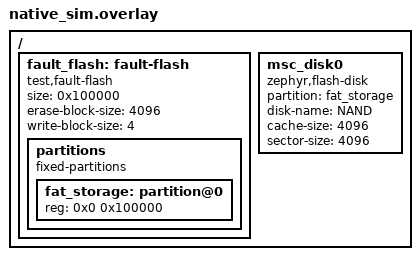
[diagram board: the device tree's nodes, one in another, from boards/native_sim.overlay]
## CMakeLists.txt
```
# SPDX-License-Identifier: Apache-2.0

cmake_minimum_required(VERSION 3.20.0)

# The overlay's test,fault-flash node uses this suite's local binding
# (dts/bindings) -- must be on DTS_ROOT before Zephyr is loaded.
list(APPEND DTS_ROOT ${CMAKE_CURRENT_LIST_DIR})

find_package(Zephyr REQUIRED HINTS $ENV{ZEPHYR_BASE})
project(fat_flashdisk_fault_tests)

# The patched flashdisk driver copy (fw/drivers/flashdisk). In the
# .sdk_tripwire scenario CONFIG_DISK_DRIVER_FLASH_PATCHED=n and this adds
# nothing -- the SDK driver builds instead.
add_subdirectory(
	${CMAKE_CURRENT_LIST_DIR}/../../../drivers
	${CMAKE_CURRENT_BINARY_DIR}/app_drivers
)

target_sources(app PRIVATE src/main.cpp src/fault_flash.c)
```

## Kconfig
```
source "Kconfig.zephyr"

rsource "../../../drivers/Kconfig"

# The fault_flash test driver has no Kconfig of its own (it is an app source);
# this promptless symbol supplies the flash-capability selects a driver
# Kconfig would normally make, so flashdisk_with_erase() and the page-layout
# verification see a real erase-required device.
config TEST_FAULT_FLASH
	bool
	default y
	select FLASH_HAS_EXPLICIT_ERASE
	select FLASH_HAS_PAGE_LAYOUT
	select FLASH_HAS_DRIVER_ENABLED
```

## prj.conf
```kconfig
CONFIG_ZTEST=y
CONFIG_CPP=y
CONFIG_STD_CPP2B=y
CONFIG_REQUIRES_FULL_LIBCPP=y
CONFIG_REQUIRES_FULL_LIBC=y
CONFIG_FLASH=y
CONFIG_FLASH_MAP=y
CONFIG_FLASH_PAGE_LAYOUT=y
CONFIG_FILE_SYSTEM=y
CONFIG_FAT_FILESYSTEM_ELM=y
CONFIG_FILE_SYSTEM_MKFS=y
CONFIG_DISK_ACCESS=y
CONFIG_HEAP_MEM_POOL_SIZE=16384

# Proto0 disk geometry: FatFS sector == flash erase page == 4096 (the SDK
# default of 512 would silently change the failure surface under test).
CONFIG_FS_FATFS_MAX_SS=4096

# Mirror proto0's FatFS threading configuration (issue #380 layer 2) so this
# suite builds and exercises the FS stack the device actually runs — review
# finding: before this, no native_sim build compiled FS_FATFS_REENTRANT at
# all. The concurrency hammer test depends on these.
CONFIG_FS_FATFS_LFN=y
CONFIG_FS_FATFS_LFN_MODE_STACK=y
CONFIG_FS_FATFS_REENTRANT=y

# The unit under test — the issue #380 backport. The .sdk_tripwire scenario
# overrides both to build against the SDK driver instead.
CONFIG_DISK_DRIVER_FLASH=n
CONFIG_DISK_DRIVER_FLASH_PATCHED=y
```

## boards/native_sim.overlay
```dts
/*
 * A fault-injectable flash controller under the same fat_storage/flash-disk
 * shape proto0 uses, but with proto0's REAL disk geometry (sector-size 4096 ==
 * erase page == FatFS sector, matching the Partition Manager extra_params),
 * unlike fat_corrupt's 512-byte sectors. The fault_flash driver in src/ backs
 * it with RAM and fails flash ops on command, which is the only way to
 * exercise the flashdisk error paths FatFS depends on (issue #380).
 */
/ {
	fault_flash: fault-flash {
		compatible = "test,fault-flash";
		size = <0x100000>;		/* 1 MB — f_mkfs needs >= 128 sectors at 4 KB */
		erase-block-size = <4096>;
		write-block-size = <4>;
		#address-cells = <1>;
		#size-cells = <1>;

		partitions {
			compatible = "fixed-partitions";
			#address-cells = <1>;
			#size-cells = <1>;

			fat_storage: partition@0 {
				reg = <0x0 0x100000>;
			};
		};
	};

	msc_disk0 {
		compatible = "zephyr,flash-disk";
		partition = <&fat_storage>;
		disk-name = "NAND";
		cache-size = <4096>;
		sector-size = <4096>;
	};
};
```

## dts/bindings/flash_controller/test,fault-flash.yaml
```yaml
# Test-only binding for the fat_flashdisk_fault suite. Lives inside the test
# directory (DTS_ROOT appended in its CMakeLists.txt) so the compatible never
# leaks into real board DTS.

description: RAM-backed flash controller with injectable per-op failures (issue #380 suite)

compatible: "test,fault-flash"

include: base.yaml

properties:
  size:
    type: int
    required: true
    description: Total backing-store size in bytes

  erase-block-size:
    type: int
    required: true
    description: Uniform erase page size in bytes

  write-block-size:
    type: int
    required: true
    description: Program alignment in bytes
```

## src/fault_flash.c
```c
/*
 * Test-only RAM-backed flash driver with injectable failures.
 *
 * Backs the fat_storage partition in this suite's native_sim overlay. Same
 * app-source-driver style the repo's emulator suites use — no Kconfig of its
 * own, capabilities are selected by the suite-local Kconfig (TEST_FAULT_FLASH).
 */

#define DT_DRV_COMPAT test_fault_flash

#include "fault_flash.h"

#include <string.h>
#include <zephyr/device.h>
#include <zephyr/drivers/flash.h>
#include <zephyr/kernel.h>

#define BACKING_SIZE DT_INST_PROP(0, size)
#define ERASE_BLOCK  DT_INST_PROP(0, erase_block_size)
#define WRITE_BLOCK  DT_INST_PROP(0, write_block_size)

BUILD_ASSERT(BACKING_SIZE % ERASE_BLOCK == 0, "size must be a whole number of erase blocks");

static uint8_t backing[BACKING_SIZE];

static struct {
	unsigned int op_mask;
	unsigned int remaining;
	off_t win_start;
	size_t win_len;
	unsigned int injected;
	unsigned int op_delay_ms;
} fault;

void fault_flash_set_op_delay_ms(unsigned int ms)
{
	fault.op_delay_ms = ms;
}

static void op_delay(void)
{
	if (fault.op_delay_ms != 0) {
		k_msleep(fault.op_delay_ms);
	}
}

void fault_flash_arm(unsigned int op_mask, unsigned int count, off_t win_start, size_t win_len)
{
	fault.op_mask = op_mask;
	fault.remaining = count;
	fault.win_start = win_start;
	fault.win_len = win_len;
	fault.injected = 0;
}

void fault_flash_disarm(void)
{
	fault_flash_arm(0, 0, 0, 0);
	fault.op_delay_ms = 0;
}

unsigned int fault_flash_injected(void)
{
	return fault.injected;
}

static bool fault_hits(unsigned int op, off_t addr, size_t len)
{
	if ((fault.op_mask & op) == 0 || fault.remaining == 0) {
		return false;
	}
	if (fault.win_len != 0 &&
	    ((addr + (off_t)len <= fault.win_start) ||
	     (addr >= fault.win_start + (off_t)fault.win_len))) {
		return false;
	}
	fault.remaining--;
	fault.injected++;
	return true;
}

static bool in_bounds(off_t offset, size_t len)
{
	return offset >= 0 && len <= (size_t)BACKING_SIZE && (size_t)offset <= BACKING_SIZE - len;
}

static int fault_flash_read(const struct device *dev, off_t offset, void *data, size_t len)
{
	ARG_UNUSED(dev);
	op_delay();
	if (!in_bounds(offset, len)) {
		return -EINVAL;
	}
	if (fault_hits(FAULT_FLASH_OP_READ, offset, len)) {
		return -EIO;
	}
	memcpy(data, &backing[offset], len);
	return 0;
}

static int fault_flash_write(const struct device *dev, off_t offset, const void *data, size_t len)
{
	ARG_UNUSED(dev);
	op_delay();
	if (!in_bounds(offset, len) || (offset % WRITE_BLOCK) != 0 || (len % WRITE_BLOCK) != 0) {
		return -EINVAL;
	}
	if (fault_hits(FAULT_FLASH_OP_WRITE, offset, len)) {
		return -EIO;
	}
	/* NOR programming can only clear bits: refuse to program un-erased
	 * media instead of silently overwriting like RAM would. This is what
	 * lets the suite catch a flashdisk_cache_commit that ever skips its
	 * erase (review finding on the first revision) — on real hardware that
	 * bug produces bitwise-AND garbage in FAT sectors, i.e. issue #380's
	 * corruption class, and a plain memcpy double could never see it. */
	for (size_t i = 0; i < len; i++) {
		const uint8_t want = ((const uint8_t *)data)[i];

		if ((backing[offset + i] & want) != want) {
			return -EIO;
		}
	}
	memcpy(&backing[offset], data, len);
	return 0;
}

static int fault_flash_erase(const struct device *dev, off_t offset, size_t size)
{
	ARG_UNUSED(dev);
	op_delay();
	if (!in_bounds(offset, size) || (offset % ERASE_BLOCK) != 0 || (size % ERASE_BLOCK) != 0) {
		return -EINVAL;
	}
	if (fault_hits(FAULT_FLASH_OP_ERASE, offset, size)) {
		return -EIO;
	}
	/* Erase really blanks the page BEFORE a potential write fault is
	 * consumed by flashdisk_cache_commit's flash_write — reproducing the
	 * erase-OK/program-fail "page is 0xFF on media" hazard. */
	memset(&backing[offset], 0xFF, size);
	return 0;
}

static const struct flash_parameters fault_flash_parameters = {
	.write_block_size = WRITE_BLOCK,
	.erase_value = 0xFF,
};

static const struct flash_parameters *fault_flash_get_parameters(const struct device *dev)
{
	ARG_UNUSED(dev);
	return &fault_flash_parameters;
}

static const struct flash_pages_layout fault_flash_pages_layout = {
	.pages_count = BACKING_SIZE / ERASE_BLOCK,
	.pages_size = ERASE_BLOCK,
};

static void fault_flash_page_layout(const struct device *dev,
				    const struct flash_pages_layout **layout, size_t *layout_size)
{
	ARG_UNUSED(dev);
	*layout = &fault_flash_pages_layout;
	*layout_size = 1;
}

static DEVICE_API(flash, fault_flash_api) = {
	.read = fault_flash_read,
	.write = fault_flash_write,
	.erase = fault_flash_erase,
	.get_parameters = fault_flash_get_parameters,
#if defined(CONFIG_FLASH_PAGE_LAYOUT)
	.page_layout = fault_flash_page_layout,
#endif
};

static int fault_flash_init(const struct device *dev)
{
	ARG_UNUSED(dev);
	memset(backing, 0xFF, sizeof(backing));
	return 0;
}

DEVICE_DT_INST_DEFINE(0, fault_flash_init, NULL, NULL, NULL, POST_KERNEL,
		      CONFIG_FLASH_INIT_PRIORITY, &fault_flash_api);
```

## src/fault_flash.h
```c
/*
 * Control surface for the test-only fault-injecting flash driver
 * (fault_flash.c, DT compatible "test,fault-flash").
 *
 * A fault is armed for an op mask, a shot count and an optional address
 * window; each matching flash op consumes one shot and fails with -EIO,
 * exactly like the nordic,qspi-nor driver reports a WREN/program/erase
 * failure on hardware (issue #380).
 */

#ifndef FW_TESTS_STORAGE_FAT_FLASHDISK_FAULT_SRC_FAULT_FLASH_H_
#define FW_TESTS_STORAGE_FAT_FLASHDISK_FAULT_SRC_FAULT_FLASH_H_

#include <stddef.h>
#include <sys/types.h>

#ifdef __cplusplus
extern "C" {
#endif

#define FAULT_FLASH_OP_READ  (1U << 0)
#define FAULT_FLASH_OP_WRITE (1U << 1)
#define FAULT_FLASH_OP_ERASE (1U << 2)

/* Fail the next `count` ops matching `op_mask` that touch
 * [win_start, win_start + win_len); win_len == 0 means any address. */
void fault_flash_arm(unsigned int op_mask, unsigned int count, off_t win_start, size_t win_len);

void fault_flash_disarm(void);

/* Number of ops actually failed since the last arm/disarm reset. */
unsigned int fault_flash_injected(void);

/* Sleep this long at the top of every flash op (0 = off, the default).
 * Purpose: on native_sim a RAM-backed flash op has no blocking point, so
 * concurrent threads never interleave inside FatFS/flashdisk critical
 * sections and a concurrency test proves nothing (see the add-fw-test
 * skill's concurrency note). A small delay creates real preemption windows. */
void fault_flash_set_op_delay_ms(unsigned int ms);

#ifdef __cplusplus
}
#endif

#endif /* FW_TESTS_STORAGE_FAT_FLASHDISK_FAULT_SRC_FAULT_FLASH_H_ */
```
